# DDRSS0_CTL_CFG register map
Vendor: Texas Instruments
Registers are 32-bit, read-write, reset 0x0 unless marked. A register's access mark holds for its fields unless they carry their own. Offsets are as the file gives them; [hi:lo] are bit positions.

## DDRSS0_CTL_CFG (part 3 of 5)
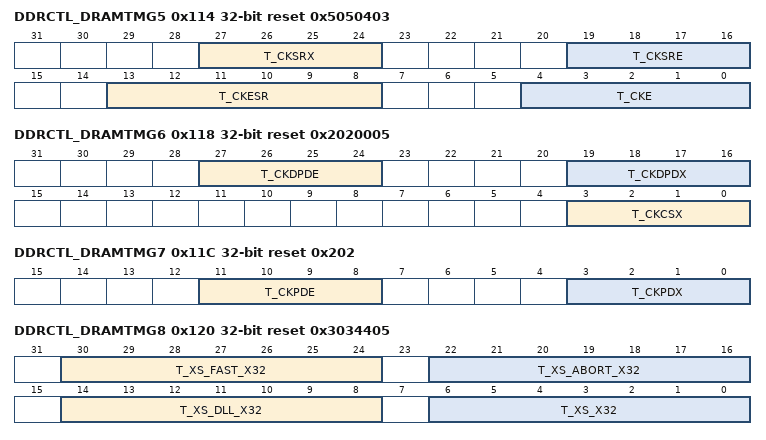
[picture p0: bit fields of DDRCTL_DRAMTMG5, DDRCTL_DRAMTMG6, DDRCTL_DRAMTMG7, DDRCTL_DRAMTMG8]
0x114 DDRCTL_DRAMTMG5 reset 0x5050403 — SDRAM Timing Register 5
  [27:24] T_CKSRX — This is the time before Self Refresh Exit that CK is maintained as a valid clock before issuing SRX.Specifies the clock stable time before SRX. Recommended settings: - mDDR: 1 - LPDDR2: 2 - LPDDR3: 2 - LPDDR4: tCKCKEH - DDR2: 1 - DDR3: tCKSRX - DDR4: tCKSRX When the controller is operating in 1:2 frequency ratio mode, program this to recommended value divided by two and round it up to next integer. Programming Mode: Quasi-dynamic Group 2 and Group 4
  [19:16] T_CKSRE — This is the time after Self Refresh Down Entry that CK is maintained as a valid clock.Specifies the clock disable delay after SRE. Recommended settings: - mDDR: 0 - LPDDR2: 2 - LPDDR3: 2 - LPDDR4: tCKELCK - DDR2: 1 - DDR3: max (10 ns, 5 tCK) - DDR4: max (10 ns, 5 tCK) (+ PL(parity latency)(*)) (*)Only if DDRCTL_CRCPARCTL1.caparity_disable_before_sr=0, this register should be increased by PL. When the controller is operating in 1:2 frequency ratio mode, program this to recommended value divided by two and round it up to next integer. Programming Mode: Quasi-dynamic Group 2 and Group 4
  [13:8] T_CKESR — Minimum CKE low width for Self refresh or Self refresh power down entry to exit timing in memory clock cycles.Recommended settings: - mDDR: tRFC - LPDDR2: tCKESR - LPDDR3: tCKESR - LPDDR4: max(tCKE, tSR) - DDR2: tCKE - DDR3: tCKE + 1 - DDR4: tCKE + 1 (+ PL(parity latency)(*)) (*)Only if DDRCTL_CRCPARCTL1.caparity_disable_before_sr=0, this register should be increased by PL. When the controller is operating in 1:2 frequency ratio mode, program this to recommended value divided by two and round it up to next integer. Programming Mode: Quasi-dynamic Group 2 and Group 4
  [4:0] T_CKE — Minimum number of cycles of CKE HIGH/LOW during power-down and self refresh.- LPDDR2/LPDDR3 mode: Set this to the larger of tCKE or tCKESR - LPDDR4 mode: Set this to the larger of tCKE or tSR. - Non-LPDDR2/non-LPDDR3/non-LPDDR4 designs: Set this to tCKE value. When the controller is operating in 1:2 frequency ratio mode, program this to (value described above)/2 and round it up to the next integer value. Unit: Clocks. Programming Mode: Quasi-dynamic Group 2 and Group 4
0x118 DDRCTL_DRAMTMG6 reset 0x2020005 — SDRAM Timing Register 6
  [27:24] T_CKDPDE — This is the time after Deep Power Down Entry that CK is maintained as a valid clock.Specifies the clock disable delay after DPDE. Recommended settings: - mDDR: 0 - LPDDR2: 2 - LPDDR3: 2 When the controller is operating in 1:2 frequency ratio mode, program this to recommended value divided by two and round it up to next integer. This is only present for designs supporting mDDR or LPDDR2/LPDDR3 devices. Programming Mode: Quasi-dynamic Group 2 and Group 4
  [19:16] T_CKDPDX — This is the time before Deep Power Down Exit that CK is maintained as a valid clock before issuing DPDX.Specifies the clock stable time before DPDX. Recommended settings: - mDDR: 1 - LPDDR2: 2 - LPDDR3: 2 When the controller is operating in 1:2 frequency ratio mode, program this to recommended value divided by two and round it up to next integer. This is only present for designs supporting mDDR or LPDDR2 devices. Programming Mode: Quasi-dynamic Group 2 and Group 4
  [3:0] T_CKCSX — This is the time before Clock Stop Exit that CK is maintained as a valid clock before issuing Clock Stop Exit.Specifies the clock stable time before next command after Clock Stop Exit. Recommended settings: - mDDR: 1 - LPDDR2: tXP + 2 - LPDDR3: tXP + 2 - LPDDR4: tXP + 2 When the controller is operating in 1:2 frequency ratio mode, program this to recommended value divided by two and round it up to next integer. This is only present for designs supporting mDDR or LPDDR2/LPDDR3/LPDDR4 devices. Programming Mode: Quasi-dynamic Group 2 and Group 4
0x11C DDRCTL_DRAMTMG7 reset 0x202 — SDRAM Timing Register 7
  [11:8] T_CKPDE — This is the time after Power Down Entry that CK is maintained as a valid clock.Specifies the clock disable delay after PDE. Recommended settings: - mDDR: 0 - LPDDR2: 2 - LPDDR3: 2 - LPDDR4: tCKELCK When using DDR2/3/4 SDRAM, this register should be set to the same value as DDRCTL_DRAMTMG5.t_cksre. When the controller is operating in 1:2 frequency ratio mode, program this to recommended value divided by two and round it up to next integer. This is only present for designs supporting mDDR or LPDDR2/LPDDR3/LPDDR4 devices. Programming Mode: Quasi-dynamic Group 2 and Group 4
  [3:0] T_CKPDX — This is the time before Power Down Exit that CK is maintained as a valid clock before issuing PDX.Specifies the clock stable time before PDX. Recommended settings: - mDDR: 0 - LPDDR2: 2 - LPDDR3: 2 - LPDDR4: 2 When using DDR2/3/4 SDRAM, this register should be set to the same value as DDRCTL_DRAMTMG5.t_cksrx. When the controller is operating in 1:2 frequency ratio mode, program this to recommended value divided by two and round it up to next integer. This is only present for designs supporting mDDR or LPDDR2/LPDDR3/LPDDR4 devices. Programming Mode: Quasi-dynamic Group 2 and Group 4
0x120 DDRCTL_DRAMTMG8 reset 0x3034405 — SDRAM Timing Register 8
  [30:24] T_XS_FAST_X32 — tXS_FAST: Exit Self Refresh to ZQCL, ZQCS and MRS (only CL, WR, RTP and Geardown mode).When the controller is operating in 1:2 frequency ratio mode, program this to the above value divided by 2 and round up to next integer value. Unit: Multiples of 32 clocks. Note: This is applicable to only ZQCL/ZQCS commands. Note: Ensure this is less than or equal to t_xs_x32. Programming Mode: Quasi-dynamic Group 2 and Group 4
  [22:16] T_XS_ABORT_X32 — tXS_ABORT: Exit Self Refresh to commands not requiring a locked DLL in Self Refresh Abort.When the controller is operating in 1:2 frequency ratio mode, program this to the above value divided by 2 and round up to next integer value. Unit: Multiples of 32 clocks. Note: Ensure this is less than or equal to t_xs_x32. Programming Mode: Quasi-dynamic Group 2 and Group 4
  [14:8] T_XS_DLL_X32 — tXSDLL: Exit Self Refresh to commands requiring a locked DLL.When the controller is operating in 1:2 frequency ratio mode, program this to the above value divided by 2 and round up to next integer value. Unit: Multiples of 32 clocks. Note: Used only for DDR2, DDR3 and DDR4 SDRAMs. Programming Mode: Quasi-dynamic Group 2 and Group 4
  [6:0] T_XS_X32 — tXS: Exit Self Refresh to commands not requiring a locked DLL.When the controller is operating in 1:2 frequency ratio mode, program this to the above value divided by 2 and round up to next integer value. Unit: Multiples of 32 clocks. Note: Used only for DDR2, DDR3 and DDR4 SDRAMs. Programming Mode: Quasi-dynamic Group 2 and Group 4
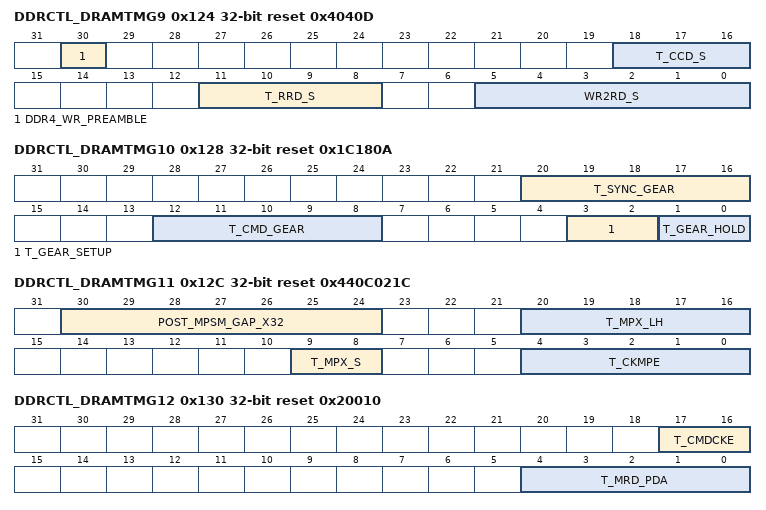
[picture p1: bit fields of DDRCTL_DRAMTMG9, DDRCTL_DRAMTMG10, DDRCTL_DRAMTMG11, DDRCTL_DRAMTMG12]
0x124 DDRCTL_DRAMTMG9 reset 0x4040D — SDRAM Timing Register 9
  [30] DDR4_WR_PREAMBLE — DDR4 Write preamble mode -0: 1tCK preamble - 1: 2tCK preamble Present only with MEMC_FREQ_RATIO=2 Programming Mode: Quasi-dynamic Group 2 and Group 4
  [18:16] T_CCD_S — tCCD_S: This is the minimum time between two reads or two writes for different bank group.For bank switching (from bank 'a' to bank 'b'), the minimum time is this value + 1. When the controller is operating in 1:2 frequency ratio mode, program this to (tCCD_S/2) and round it up to the next integer value. Present only in designs configured to support DDR4. Unit: clocks. Programming Mode: Quasi-dynamic Group 2 and Group 4
  [11:8] T_RRD_S — tRRD_S: Minimum time between activates from bank 'a' to bank 'b' for different bank group.When the controller is operating in 1:2 frequency ratio mode, program this to (tRRD_S/2) and round it up to the next integer value. Present only in designs configured to support DDR4. Unit: Clocks. Programming Mode: Quasi-dynamic Group 2 and Group 4
  [5:0] WR2RD_S — CWL + PL + BL/2 + tWTR_S Minimum time from write command to read command for different bank group.Includes time for bus turnaround, recovery times, and all per-bank, per-rank, and global constraints. Present only in designs configured to support DDR4. Unit: Clocks. Where: - CWL = CAS write latency - PL = Parity latency - BL = burst length. This must match the value programmed in the BL bit of the mode register to the SDRAM - tWTR_S = internal write to read command delay for different bank group. This comes directly from the SDRAM specification. When the controller is operating in 1:2 mode, divide the value calculated using the above equation by 2, and round it up to next integer. Programming Mode: Quasi-dynamic Group 1 and Group 2 and Group 4
0x128 DDRCTL_DRAMTMG10 reset 0x1C180A — SDRAM Timing Register 10
  [20:16] T_SYNC_GEAR — Indicates the time between MRS command and the sync pulse time.This must be even number of clocks. For DDR4-2666 and DDR4-3200, this parameter is defined as tMOD(min)+4nCK tMOD(min) is greater of 24nCK or 15ns 15ns / .625ns = 24 Max value for this register is 24+4 = 28 When the controller is operating in 1:2 mode, program this to (tSYNC_GEAR/2) and round it up to the next integer value. Unit: Clocks Programming Mode: Quasi-dynamic Group 2 and Group 4
  [12:8] T_CMD_GEAR — Sync pulse to first valid command.For DDR4-2666 and DDR4-3200, this parameter is defined as tMOD(min) tMOD(min) is greater of 24nCK or 15ns 15ns / .625ns = 24 Max value for this register is 24 When the controller is operating in 1:2 mode, program this to (tCMD_GEAR/2) and round it up to the next integer value. Unit: Clocks Programming Mode: Quasi-dynamic Group 2 and Group 4
  [3:2] T_GEAR_SETUP — Geardown setup time.Minimum value of this register is 1. Zero is invalid. For DDR4-2666 and DDR4-3200, this parameter is defined as 2 clks When the controller is operating in 1:2 frequency ratio mode, program this to (tGEAR_setup/2) and round it up to the next integer value. Unit: Clocks Programming Mode: Quasi-dynamic Group 2 and Group 4
  [1:0] T_GEAR_HOLD — Geardown hold time.Minimum value of this register is 1. Zero is invalid. For DDR4-2666 and DDR4-3200, this parameter is defined as 2 clks When the controller is operating in 1:2 frequency ratio mode, program this to (tGEAR_hold/2) and round it up to the next integer value. Unit: Clocks Programming Mode: Quasi-dynamic Group 2 and Group 4
0x12C DDRCTL_DRAMTMG11 reset 0x440C021C — SDRAM Timing Register 11
  [30:24] POST_MPSM_GAP_X32 — tXMPDLL: This is the minimum Exit MPSM to commands requiring a locked DLL.When the controller is operating in 1:2 frequency ratio mode, program this to (tXMPDLL/2) and round it up to the next integer value. Present only in designs configured to support DDR4. Unit: Multiples of 32 clocks. Programming Mode: Quasi-dynamic Group 2 and Group 4
  [20:16] T_MPX_LH — tMPX_LH: This is the minimum CS_n Low hold time to CKE rising edge.When the controller is operating in 1:2 frequency ratio mode, program this to RoundUp(tMPX_LH/2)+1. Present only in designs configured to support DDR4. Unit: clocks. Programming Mode: Quasi-dynamic Group 2 and Group 4
  [9:8] T_MPX_S — tMPX_S: Minimum time CS setup time to CKE.When the controller is operating in 1:2 frequency ratio mode, program this to (tMPX_S/2) and round it up to the next integer value. Present only in designs configured to support DDR4. Unit: Clocks. Programming Mode: Quasi-dynamic Group 2 and Group 4
  [4:0] T_CKMPE — tCKMPE: Minimum valid clock requirement after MPSM entry.Present only in designs configured to support DDR4. Unit: Clocks. When the controller is operating in 1:2 frequency ratio mode, divide the value calculated using the above equation by 2, and round it up to next integer. Programming Mode: Quasi-dynamic Group 2 and Group 4
0x130 DDRCTL_DRAMTMG12 reset 0x20010 — SDRAM Timing Register 12
  [17:16] T_CMDCKE — tCMDCKE: Delay from valid command to CKE input LOW.Set this to the larger of tESCKE or tCMDCKE When the controller is operating in 1:2 frequency ratio mode, program this to (max(tESCKE, tCMDCKE)/2) and round it up to the next integer value. Programming Mode: Quasi-dynamic Group 2 and Group 4
  [4:0] T_MRD_PDA — tMRD_PDA: This is the Mode Register Set command cycle time in PDA mode.When the controller is operating in 1:2 frequency ratio mode, program this to (tMRD_PDA/2) and round it up to the next integer value. Programming Mode: Quasi-dynamic Group 2 and Group 4
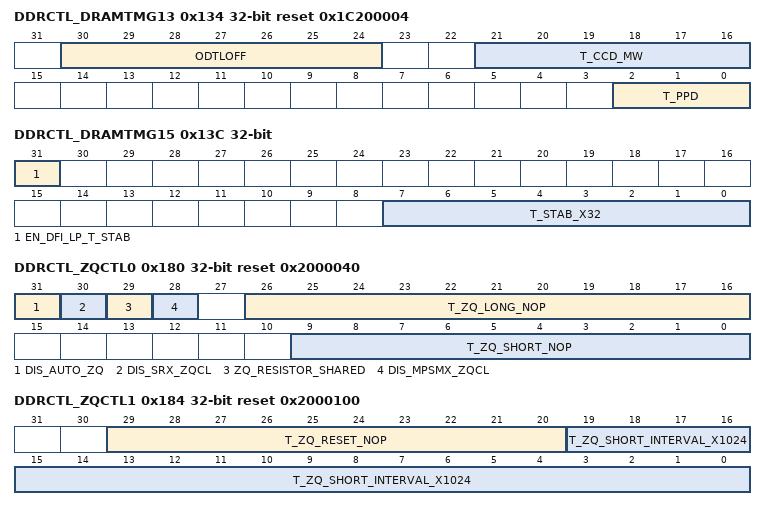
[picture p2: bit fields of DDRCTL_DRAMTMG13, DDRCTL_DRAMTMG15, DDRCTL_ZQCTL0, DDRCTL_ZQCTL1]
0x134 DDRCTL_DRAMTMG13 reset 0x1C200004 — SDRAM Timing Register 13
  [30:24] ODTLOFF — LPDDR4: tODTLoff: This is the latency from CAS-2 command to tODToff reference. When the controller is operating in 1:2 frequency ratio mode, program this to (tODTLoff/2) and round it up to the next integer value. Unit: Clocks. Programming Mode: Quasi-dynamic Group 2 and Group 4
  [21:16] T_CCD_MW — LPDDR4: tCCDMW: This is the minimum time from write or masked write to masked write command for same bank. When the controller is operating in 1:2 frequency ratio mode, program this to (tCCDMW/2) and round it up to the next integer value. Unit: Clocks. Programming Mode: Quasi-dynamic Group 2 and Group 4
  [2:0] T_PPD — LPDDR4: tPPD: This is the minimum time from precharge to precharge command. When the controller is operating in 1:2 frequency ratio mode, program this to (tPPD/2) and round it up to the next integer value. Unit: Clocks. Programming Mode: Quasi-dynamic Group 2 and Group 4
0x138 DDRCTL_DRAMTMG14 reset 0xA0 — SDRAM Timing Register 14
  [11:0] T_XSR — tXSR: Exit Self Refresh to any command.When the controller is operating in 1:2 frequency ratio mode, program this to the above value divided by 2 and round up to next integer value. Note: Used only for mDDR/LPDDR2/LPDDR3/LPDDR4 mode. Programming Mode: Quasi-dynamic Group 2 and Group 4
0x13C DDRCTL_DRAMTMG15 — SDRAM Timing Register 15
  [31] EN_DFI_LP_T_STAB — -1 - Enable using tSTAB when exiting DFI LP. Needs to be set when the PHY is stopping the clock during DFI LP to save maximum power. - 0 - Disable using tSTAB when exiting DFI LP Programming Mode: Quasi-dynamic Group 2 and Group 4
  [7:0] T_STAB_X32 — tSTAB: Stabilization time.It is required in the following two cases for DDR3/DDR4 RDIMM : - when exiting power saving mode, if the clock was stopped, after re-enabling it the clock must be stable for a time specified by tSTAB - in the case of input clock frequency change (DDR4) - after issuing control words that refers to clock timing (Specification: 6us for DDR3, 5us for DDR4) When the controller is operating in 1:2 frequency ratio mode, program this to recommended value divided by two and round it up to next integer. Unit: Multiples of 32 clock cycles. Programming Mode: Quasi-dynamic Group 2 and Group 4
0x180 DDRCTL_ZQCTL0 reset 0x2000040 — ZQ Control Register 0
  [31] DIS_AUTO_ZQ — -1 - Disable uMCTL2 generation of ZQCS/MPC(ZQ calibration) command. Register DDRCTL_DBGCMD.zq_calib_short can be used instead to issue ZQ calibration request from APB module. - 0 - Internally generate ZQCS/MPC(ZQ calibration) commands based on DDRCTL_ZQCTL1.t_zq_short_interval_x1024. This is only present for designs supporting DDR3/DDR4 or LPDDR2/LPDDR3/LPDDR4 devices. Programming Mode: Dynamic
  [30] DIS_SRX_ZQCL — -1 - Disable issuing of ZQCL/MPC(ZQ calibration) command at Self-Refresh/SR-Powerdown exit. Only applicable when run in DDR3 or DDR4 or LPDDR2 or LPDDR3 or LPDDR4 mode. - 0 - Enable issuing of ZQCL/MPC(ZQ calibration) command at Self-Refresh/SR-Powerdown exit. Only applicable when run in DDR3 or DDR4 or LPDDR2 or LPDDR3 or LPDDR4 mode. This is only present for designs supporting DDR3/DDR4 or LPDDR2/LPDDR3/LPDDR4 devices. Programming Mode: Quasi-dynamic Group 2 and Group 4
  [29] ZQ_RESISTOR_SHARED — -1 - Denotes that ZQ resistor is shared between ranks. Means ZQinit/ZQCL/ZQCS/MPC(ZQ calibration) commands are sent to one rank at a time with tZQinit/tZQCL/tZQCS/tZQCAL/tZQLAT timing met between commands so that commands to different ranks do not overlap. - 0 - ZQ resistor is not shared. This is only present for designs supporting DDR3/DDR4 or LPDDR2/LPDDR3/LPDDR4 devices. Programming Mode: Static
  [28] DIS_MPSMX_ZQCL — -1 - Disable issuing of ZQCL command at Maximum Power Saving Mode exit. Only applicable when run in DDR4 mode. - 0 - Enable issuing of ZQCL command at Maximum Power Saving Mode exit. Only applicable when run in DDR4 mode. This is only present for designs supporting DDR4 devices. Note: Do not issue ZQCL command at Maximum Power Save Mode exit if the UMCTL2_SHARED_AC configuration parameter is set. Program it to 1'b1. The software can send ZQCS after exiting MPSM mode. Programming Mode: Static
  [26:16] T_ZQ_LONG_NOP — tZQoper for DDR3/DDR4, tZQCL for LPDDR2/LPDDR3, tZQCAL for LPDDR4: Number of DFI clock cycles of NOP required after a ZQCL (ZQ calibration long)/MPC(ZQ Start) command is issued to SDRAM. When the controller is operating in 1:2 frequency ratio mode: DDR3/DDR4: program this to tZQoper/2 and round it up to the next integer value. LPDDR2/LPDDR3: program this to tZQCL/2 and round it up to the next integer value. LPDDR4: program this to tZQCAL/2 and round it up to the next integer value. This is only present for designs supporting DDR3/DDR4 or LPDDR2/LPDDR3/LPDDR4 devices. Programming Mode: Static
  [9:0] T_ZQ_SHORT_NOP — tZQCS for DDR3/DD4/LPDDR2/LPDDR3, tZQLAT for LPDDR4: Number of DFI clock cycles of NOP required after a ZQCS (ZQ calibration short)/MPC(ZQ Latch) command is issued to SDRAM. When the controller is operating in 1:2 frequency ratio mode, program this to tZQCS/2 and round it up to the next integer value. This is only present for designs supporting DDR3/DDR4 or LPDDR2/LPDDR3/LPDDR4 devices. Programming Mode: Static
0x184 DDRCTL_ZQCTL1 reset 0x2000100 — ZQ Control Register 1
  [29:20] T_ZQ_RESET_NOP — tZQReset: Number of DFI clock cycles of NOP required after a ZQReset (ZQ calibration Reset) command is issued to SDRAM.When the controller is operating in 1:2 frequency ratio mode, program this to tZQReset/2 and round it up to the next integer value. This is only present for designs supporting LPDDR2/LPDDR3/LPDDR4 devices. Programming Mode: Static
  [19:0] T_ZQ_SHORT_INTERVAL_X1024 — Average interval to wait between automatically issuing ZQCS (ZQ calibration short)/MPC(ZQ calibration) commands to DDR3/DDR4/LPDDR2/LPDDR3/LPDDR4 devices.Meaningless, if DDRCTL_ZQCTL0.dis_auto_zq=1. Unit: 1024 DFI clock cycles. This is only present for designs supporting DDR3/DDR4 or LPDDR2/LPDDR3/LPDDR4 devices. Programming Mode: Static
0x188 DDRCTL_ZQCTL2 access not given — ZQ Control Register 2
  [0] ZQ_RESET — Setting this register bit to 1 triggers a ZQ Reset operation.When the ZQ Reset operation is complete, the uMCTL2 automatically clears this bit. It is recommended NOT to set this signal if in Init, Self-Refresh(except LPDDR4) or SR-Powerdown(LPDDR4) or Deep power-down operating modes. This is only present for designs supporting LPDDR2/LPDDR3/LPDDR4 devices. Programming Mode: Dynamic (access W1S)
0x18C DDRCTL_ZQSTAT ro — ZQ Status Register
  [0] ZQ_RESET_BUSY — SoC core may initiate a ZQ Reset operation only if this signal is low.This signal goes high in the clock after the uMCTL2 accepts the ZQ Reset request. It goes low when the ZQ Reset command is issued to the SDRAM and the associated NOP period is over. It is recommended not to perform ZQ Reset commands when this signal is high. - 0 - Indicates that the SoC core can initiate a ZQ Reset operation - 1 - Indicates that ZQ Reset operation is in progress Programming Mode: Dynamic
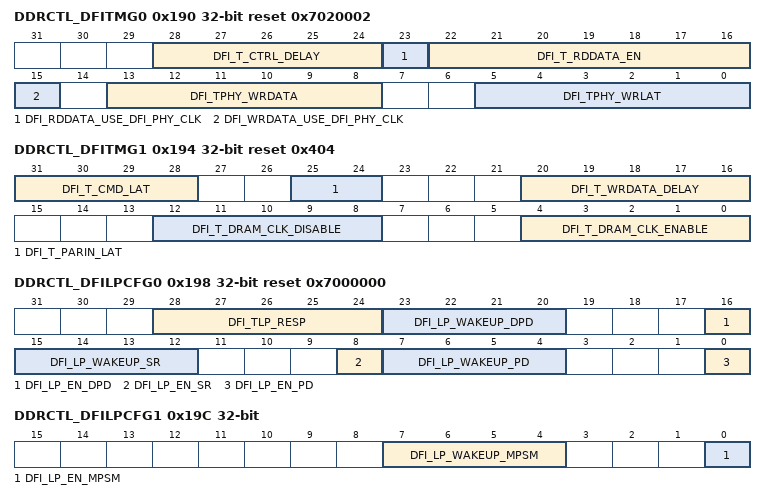
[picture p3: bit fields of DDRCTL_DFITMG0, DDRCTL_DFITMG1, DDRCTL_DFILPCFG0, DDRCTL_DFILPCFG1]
0x190 DDRCTL_DFITMG0 reset 0x7020002 — DFI Timing Register 0
  [28:24] DFI_T_CTRL_DELAY — Specifies the number of DFI clock cycles after an assertion or de-assertion of the DFI control signals that the control signals at the PHY-DRAM interface reflect the assertion or de-assertion.If the DFI clock and the memory clock are not phase-aligned, this timing parameter should be rounded up to the next integer value. Note that if using RDIMM/LRDIMM, it is necessary to increment this parameter by RDIMM's/LRDIMM's extra cycle of latency in terms of DFI clock. Programming Mode: Quasi-dynamic Group 4
  [23] DFI_RDDATA_USE_DFI_PHY_CLK — Defines whether dfi_rddata_en/dfi_rddata/dfi_rddata_valid is generated using HDR (DFI clock) or SDR (DFI PHY clock) values.Selects whether value in DDRCTL_DFITMG0.dfi_t_rddata_en is in terms of HDR (DFI clock) or SDR (DFI PHY clock) cycles: - 0 in terms of HDR (DFI clock) cycles - 1 in terms of SDR (DFI PHY clock) cycles Refer to PHY specification for correct value. If using a DWC DDR3/2 PHY, DWC DDR2/3-Lite/mDDR PHY, DWC DDR multiPHY or DWC Gen2 DDR multiPHY, this field must be set to 0 otherwise: - If MEMC_PROG_FREQ_RATIO=1 and DDRCTL_MSTR.frequency_ratio=1, this field should be set to 0 - Else, it must be set to 1 Programming Mode: Static
  [22:16] DFI_T_RDDATA_EN — Time from the assertion of a read command on the DFI interface to the assertion of the dfi_rddata_en signal.Refer to PHY specification for correct value. This corresponds to the DFI parameter trddata_en. Note that, depending on the PHY, if using RDIMM/LRDIMM, it may be necessary to use the adjusted value of CL in the calculation of trddata_en. This is to compensate for the extra cycle(s) of latency through the RDIMM/LRDIMM. Unit: DFI clock cycles or DFI PHY clock cycles, depending on DDRCTL_DFITMG0.dfi_rddata_use_dfi_phy_clk. Programming Mode: Quasi-dynamic Group 1 and Group 4
  [15] DFI_WRDATA_USE_DFI_PHY_CLK — Defines whether dfi_wrdata_en/dfi_wrdata/dfi_wrdata_mask is generated using HDR (DFI clock) or SDR (DFI PHY clock) values Selects whether value inDDRCTL_DFITMG0.dfi_tphy_wrlat is in terms of HDR (DFI clock) or SDR (DFI PHY clock) cycles Selects whether value in DDRCTL_DFITMG0.dfi_tphy_wrdata is in terms of HDR (DFI clock) or SDR (DFI PHY clock) cycles - 0 in terms of HDR (DFI clock) cycles - 1 in terms of SDR (DFI PHY clock) cycles Refer to PHY specification for correct value. If using a DWC DDR3/2 PHY, DWC DDR2/3-Lite/mDDR PHY, DWC DDR multiPHY or DWC Gen2 DDR multiPHY, this field must be set to 0 otherwise: - If MEMC_PROG_FREQ_RATIO=1 and DDRCTL_MSTR.frequency_ratio=1, this field should be set to 0 - Else, it must be set to 1 Programming Mode: Static
  [13:8] DFI_TPHY_WRDATA — Specifies the number of clock cycles between when dfi_wrdata_en is asserted to when the associated write data is driven on the dfi_wrdata signal.This corresponds to the DFI timing parameter tphy_wrdata. Refer to PHY specification for correct value. Note, max supported value is 8. Unit: DFI clock cycles or DFI PHY clock cycles, depending on DDRCTL_DFITMG0.dfi_wrdata_use_dfi_phy_clk. Programming Mode: Quasi-dynamic Group 4
  [5:0] DFI_TPHY_WRLAT — Write latency Number of clocks from the write command to write data enable (dfi_wrdata_en).This corresponds to the DFI timing parameter tphy_wrlat. Refer to PHY specification for correct value.Note that, depending on the PHY, if using RDIMM/LRDIMM, it may be necessary to use the adjusted value of CL in the calculation of tphy_wrlat. This is to compensate for the extra cycle(s) of latency through the RDIMM/LRDIMM. For LPDDR4, dfi_tphy_wrlat&gt;60 is not supported. Unit: DFI clock cycles or DFI PHY clock cycles, depending on DDRCTL_DFITMG0.dfi_wrdata_use_dfi_phy_clk. Programming Mode: Quasi-dynamic Group 1 and Group 4
0x194 DDRCTL_DFITMG1 reset 0x404 — DFI Timing Register 1
  [31:28] DFI_T_CMD_LAT — Specifies the number of DFI PHY clock cycles between when the dfi_cs signal is asserted and when the associated command is driven.This field is used for CAL mode, should be set to '0' or the value which matches the CAL mode register setting in the DRAM. If the PHY can add the latency for CAL mode, this should be set to '0'. Valid Range: 0, 3, 4, 5, 6, and 8 Programming Mode: Quasi-dynamic Group 2 and Group 4
  [25:24] DFI_T_PARIN_LAT — Specifies the number of DFI PHY clock cycles between when the dfi_cs signal is asserted and when the associated dfi_parity_in signal is driven.Programming Mode: Quasi-dynamic Group 4
  [20:16] DFI_T_WRDATA_DELAY — Specifies the number of DFI clock cycles between when the dfi_wrdata_en signal is asserted and when the corresponding write data transfer is completed on the DRAM bus.This corresponds to the DFI timing parameter twrdata_delay. Refer to PHY specification for correct value. For DFI 3.0 PHY, set to twrdata_delay, a new timing parameter introduced in DFI 3.0. For DFI 2.1 PHY, set to tphy_wrdata + (delay of DFI write data to the DRAM). Value to be programmed is in terms of DFI clocks, not PHY clocks. In FREQ_RATIO=2, divide PHY's value by 2 and round up to next integer. If using DDRCTL_DFITMG0.dfi_wrdata_use_dfi_phy_clk=1, add 1 to the value. Unit: Clocks Programming Mode: Quasi-dynamic Group 4
  [12:8] DFI_T_DRAM_CLK_DISABLE — Specifies the number of DFI clock cycles from the assertion of the dfi_dram_clk_disable signal on the DFI until the clock to the DRAM memory devices, at the PHY-DRAM boundary, maintains a low value.If the DFI clock and the memory clock are not phase aligned, this timing parameter should be rounded up to the next integer value. Programming Mode: Quasi-dynamic Group 4
  [4:0] DFI_T_DRAM_CLK_ENABLE — Specifies the number of DFI clock cycles from the de-assertion of the dfi_dram_clk_disable signal on the DFI until the first valid rising edge of the clock to the DRAM memory devices, at the PHY-DRAM boundary.If the DFI clock and the memory clock are not phase aligned, this timing parameter should be rounded up to the next integer value. Programming Mode: Quasi-dynamic Group 4
0x198 DDRCTL_DFILPCFG0 reset 0x7000000 — DFI Low Power Configuration Register 0
  [28:24] DFI_TLP_RESP — Setting in DFI clock cycles for DFI's tlp_resp time.Same value is used for both Power Down, Self Refresh, Deep Power Down and Maximum Power Saving modes. DFI 2.1 specification onwards, recommends using a fixed value of 7 always. Programming Mode: Static
  [23:20] DFI_LP_WAKEUP_DPD — Value in DFI clock cycles to drive on dfi_lp_wakeup signal when Deep Power Down mode is entered.Determines the DFI's tlp_wakeup time: - 0x0 - 16 cycles - 0x1 - 32 cycles - 0x2 - 64 cycles - 0x3 - 128 cycles - 0x4 - 256 cycles - 0x5 - 512 cycles - 0x6 - 1024 cycles - 0x7 - 2048 cycles - 0x8 - 4096 cycles - 0x9 - 8192 cycles - 0xA - 16384 cycles - 0xB - 32768 cycles - 0xC - 65536 cycles - 0xD - 131072 cycles - 0xE - 262144 cycles - 0xF - Unlimited This is only present for designs supporting mDDR or LPDDR2/LPDDR3 devices. Programming Mode: Static
  [16] DFI_LP_EN_DPD — Enables DFI Low Power interface handshaking during Deep Power Down Entry/Exit.- 0 - Disabled - 1 - Enabled This is only present for designs supporting mDDR or LPDDR2/LPDDR3 devices. Programming Mode: Static
  [15:12] DFI_LP_WAKEUP_SR — Value in DFI clpck cycles to drive on dfi_lp_wakeup signal when Self Refresh mode is entered.Determines the DFI's tlp_wakeup time: - 0x0 - 16 cycles - 0x1 - 32 cycles - 0x2 - 64 cycles - 0x3 - 128 cycles - 0x4 - 256 cycles - 0x5 - 512 cycles - 0x6 - 1024 cycles - 0x7 - 2048 cycles - 0x8 - 4096 cycles - 0x9 - 8192 cycles - 0xA - 16384 cycles - 0xB - 32768 cycles - 0xC - 65536 cycles - 0xD - 131072 cycles - 0xE - 262144 cycles - 0xF - Unlimited Programming Mode: Static
  [8] DFI_LP_EN_SR — Enables DFI Low Power interface handshaking during Self Refresh Entry/Exit.- 0 - Disabled - 1 - Enabled Programming Mode: Static
  [7:4] DFI_LP_WAKEUP_PD — Value in DFI clock cycles to drive on dfi_lp_wakeup signal when Power Down mode is entered.Determines the DFI's tlp_wakeup time: - 0x0 - 16 cycles - 0x1 - 32 cycles - 0x2 - 64 cycles - 0x3 - 128 cycles - 0x4 - 256 cycles - 0x5 - 512 cycles - 0x6 - 1024 cycles - 0x7 - 2048 cycles - 0x8 - 4096 cycles - 0x9 - 8192 cycles - 0xA - 16384 cycles - 0xB - 32768 cycles - 0xC - 65536 cycles - 0xD - 131072 cycles - 0xE - 262144 cycles - 0xF - Unlimited Programming Mode: Static
  [0] DFI_LP_EN_PD — Enables DFI Low Power interface handshaking during Power Down Entry/Exit.- 0 - Disabled - 1 - Enabled Programming Mode: Static
0x19C DDRCTL_DFILPCFG1 — DFI Low Power Configuration Register 1
  [7:4] DFI_LP_WAKEUP_MPSM — Value in DFI clock cycles to drive on dfi_lp_wakeup signal when Maximum Power Saving Mode is entered.Determines the DFI's tlp_wakeup time: - 0x0 - 16 cycles - 0x1 - 32 cycles - 0x2 - 64 cycles - 0x3 - 128 cycles - 0x4 - 256 cycles - 0x5 - 512 cycles - 0x6 - 1024 cycles - 0x7 - 2048 cycles - 0x8 - 4096 cycles - 0x9 - 8192 cycles - 0xA - 16384 cycles - 0xB - 32768 cycles - 0xC - 65536 cycles - 0xD - 131072 cycles - 0xE - 262144 cycles - 0xF - Unlimited This is only present for designs supporting DDR4 devices. Programming Mode: Static
  [0] DFI_LP_EN_MPSM — Enables DFI Low Power interface handshaking during Maximum Power Saving Mode Entry/Exit.- 0 - Disabled - 1 - Enabled This is only present for designs supporting DDR4 devices. Programming Mode: Static
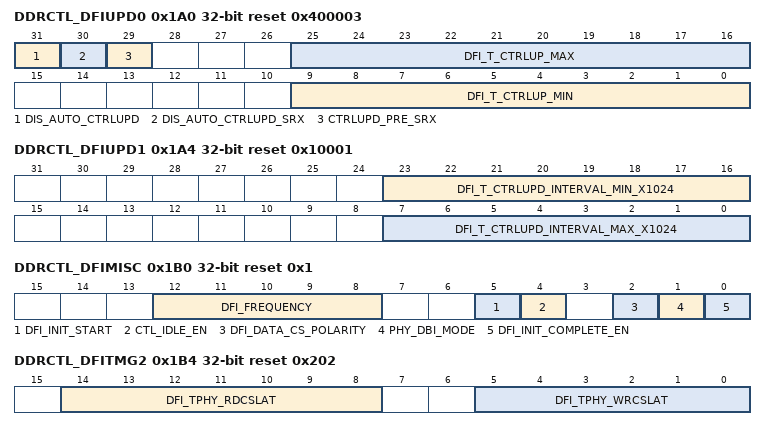
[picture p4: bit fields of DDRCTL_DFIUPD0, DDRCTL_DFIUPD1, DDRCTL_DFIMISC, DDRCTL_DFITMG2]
0x1A0 DDRCTL_DFIUPD0 reset 0x400003 — DFI Update Register 0
  [31] DIS_AUTO_CTRLUPD — When '1', disable the automatic dfi_ctrlupd_req generation by the uMCTL2.The core must issue the dfi_ctrlupd_req signal using register DDRCTL_DBGCMD.ctrlupd. When '0', uMCTL2 issues dfi_ctrlupd_req periodically. Programming Mode: Quasi-dynamic Group 3
  [30] DIS_AUTO_CTRLUPD_SRX — When '1', disable the automatic dfi_ctrlupd_req generation by the uMCTL2 at self-refresh exit.When '0', uMCTL2 issues a dfi_ctrlupd_req before or after exiting self-refresh, depending on DDRCTL_DFIUPD0.ctrlupd_pre_srx. Programming Mode: Static
  [29] CTRLUPD_PRE_SRX — Selects dfi_ctrlupd_req requirements at SRX: -0 : send ctrlupd after SRX - 1 : send ctrlupd before SRX If DDRCTL_DFIUPD0.dis_auto_ctrlupd_srx=1, this register has no impact, because no dfi_ctrlupd_req will be issued when SRX. Programming Mode: Static
  [25:16] DFI_T_CTRLUP_MAX — Specifies the maximum number of DFI clock cycles that the dfi_ctrlupd_req signal can assert.Lowest value to assign to this variable is 0x40. Programming Mode: Static
  [9:0] DFI_T_CTRLUP_MIN — Specifies the minimum number of DFI clock cycles that the dfi_ctrlupd_req signal must be asserted.The uMCTL2 expects the PHY to respond within this time. If the PHY does not respond, the uMCTL2 will de-assert dfi_ctrlupd_req after dfi_t_ctrlup_min + 2 cycles. Lowest value to assign to this variable is 0x3. Programming Mode: Static
0x1A4 DDRCTL_DFIUPD1 reset 0x10001 — DFI Update Register 1
  [23:16] DFI_T_CTRLUPD_INTERVAL_MIN_X1024 — This is the minimum amount of time between uMCTL2 initiated DFI update requests (which is executed whenever the uMCTL2 is idle).Set this number higher to reduce the frequency of update requests, which can have a small impact on the latency of the first read request when the uMCTL2 is idle. Minimum allowed value for this field is 1. Unit: 1024 DFI clock cycles Programming Mode: Static
  [7:0] DFI_T_CTRLUPD_INTERVAL_MAX_X1024 — This is the maximum amount of time between uMCTL2 initiated DFI update requests.This timer resets with each update request when the timer expires dfi_ctrlupd_req is sent and traffic is blocked until the dfi_ctrlupd_ackx is received. PHY can use this idle time to recalibrate the delay lines to the DLLs. The DFI controller update is also used to reset PHY FIFO pointers in case of data capture errors. Updates are required to maintain calibration over PVT, but frequent updates may impact performance. Minimum allowed value for this field is 1. Note: Value programmed for DDRCTL_DFIUPD1.dfi_t_ctrlupd_interval_max_x1024 must be greater than DDRCTL_DFIUPD1.dfi_t_ctrlupd_interval_min_x1024. Unit: 1024 DFI clock cycles Programming Mode: Static
0x1A8 DDRCTL_DFIUPD2 reset 0x80000000 — DFI Update Register 2
  [31] DFI_PHYUPD_EN — Enables the support for acknowledging PHY-initiated updates: -0 - Disabled - 1 - Enabled Programming Mode: Static
0x1B0 DDRCTL_DFIMISC reset 0x1 — DFI Miscellaneous Control Register
  [12:8] DFI_FREQUENCY — Indicates the operating frequency of the system.The number of supported frequencies and the mapping of signal values to clock frequencies are defined by the PHY. Programming Mode: Quasi-dynamic Group 1
  [5] DFI_INIT_START — PHY init start request signal.When asserted it triggers the PHY init start request Programming Mode: Quasi-dynamic Group 3
  [4] CTL_IDLE_EN — Enables support of ctl_idle signal, which is non-DFI related pin.See signal description of ctl_idle signal for further details of ctl_idle functionality. Programming Mode: Static
  [2] DFI_DATA_CS_POLARITY — Defines polarity of dfi_wrdata_cs and dfi_rddata_cs signals.- 0: Signals are active low - 1: Signals are active high Programming Mode: Static
  [1] PHY_DBI_MODE — DBI implemented in DDRC or PHY.- 0 - DDRC implements DBI functionality. - 1 - PHY implements DBI functionality. Present only in designs configured to support DDR4 and LPDDR4. Programming Mode: Static
  [0] DFI_INIT_COMPLETE_EN — PHY initialization complete enable signal.When asserted the dfi_init_complete signal can be used to trigger SDRAM initialisation Programming Mode: Quasi-dynamic Group 3
0x1B4 DDRCTL_DFITMG2 reset 0x202 — DFI Timing Register 2
  [14:8] DFI_TPHY_RDCSLAT — Number of DFI PHY clock cycles between when a read command is sent on the DFI control interface and when the associated dfi_rddata_cs signal is asserted.This corresponds to the DFI timing parameter tphy_rdcslat. Refer to PHY specification for correct value. Programming Mode: Quasi-dynamic Group 2 and Group 4
  [5:0] DFI_TPHY_WRCSLAT — Number of DFI PHY clock cycles between when a write command is sent on the DFI control interface and when the associated dfi_wrdata_cs signal is asserted.This corresponds to the DFI timing parameter tphy_wrcslat. Refer to PHY specification for correct value. Programming Mode: Quasi-dynamic Group 2 and Group 4
0x1B8 DDRCTL_DFITMG3 — DFI Timing Register 3
  [4:0] DFI_T_GEARDOWN_DELAY — The delay from dfi_geardown_en assertion to the time of the PHY being ready to receive commands.Refer to PHY specification for correct value. When the controller is operating in 1:2 frequency ratio mode, program this to (tgeardown_delay/2) and round it up to the next integer value. Unit: Clocks Programming Mode: Static
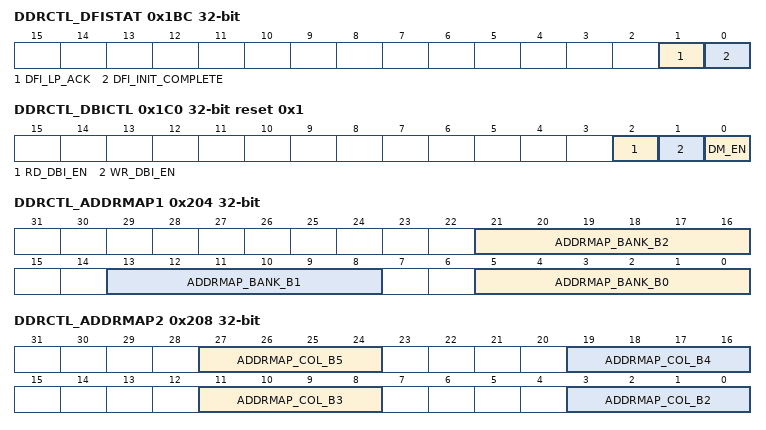
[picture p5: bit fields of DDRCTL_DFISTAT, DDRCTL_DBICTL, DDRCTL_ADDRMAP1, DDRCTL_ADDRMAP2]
0x1BC DDRCTL_DFISTAT ro — DFI Status Register
  [1] DFI_LP_ACK — Stores the value of the dfi_lp_ack input to the controller.Programming Mode: Dynamic
  [0] DFI_INIT_COMPLETE — The status flag register which announces when the DFI initialization has been completed.The DFI INIT triggered by dfi_init_start signal and then the dfi_init_complete flag is polled to know when the initialization is done. Programming Mode: Dynamic
0x1C0 DDRCTL_DBICTL reset 0x1 — DM/DBI Control Register
  [2] RD_DBI_EN — Read DBI enable signal in DDRC.- 0 - Read DBI is disabled. - 1 - Read DBI is enabled. This signal must be set the same value as DRAM's mode register. - DDR4: MR5 bit A12. When x4 devices are used, this signal must be set to 0. - LPDDR4: MR3[6] Programming Mode: Quasi-dynamic Group 1
  [1] WR_DBI_EN — Write DBI enable signal in DDRC.- 0 - Write DBI is disabled. - 1 - Write DBI is enabled. This signal must be set the same value as DRAM's mode register. - DDR4: MR5 bit A11. When x4 devices are used, this signal must be set to 0. - LPDDR4: MR3[7] Programming Mode: Quasi-dynamic Group 1
  [0] DM_EN — DM enable signal in DDRC.- 0 - DM is disabled. - 1 - DM is enabled. This signal must be set the same logical value as DRAM's mode register. - DDR4: Set this to same value as MR5 bit A10. When x4 devices are used, this signal must be set to 0. - LPDDR4: Set this to inverted value of MR13[5] which is opposite polarity from this signal Programming Mode: Quasi-dynamic Group 3
0x1C4 DDRCTL_DFIPHYMSTR reset 0x1 — DFI PHY Master
  [0] DFI_PHYMSTR_EN — Enables the PHY Master Interface: -0 - Disabled - 1 - Enabled Programming Mode: Dynamic
0x200 DDRCTL_ADDRMAP0 — Address Map Register 0
  [4:0] ADDRMAP_CS_BIT0 — Selects the HIF address bit used as rank address bit 0.Valid Range: 0 to 29, and 31 Internal Base: 6 The selected HIF address bit is determined by adding the internal base to the value of this field. If unused, set to 31 and then rank address bit 0 is set to 0. Programming Mode: Static
0x204 DDRCTL_ADDRMAP1 — Address Map Register 1
  [21:16] ADDRMAP_BANK_B2 — Selects the HIF address bit used as bank address bit 2.Valid Range: 0 to 31 and 63 Internal Base: 4 The selected HIF address bit is determined by adding the internal base to the value of this field. If unused, set to 63 and then bank address bit 2 is set to 0. Programming Mode: Static
  [13:8] ADDRMAP_BANK_B1 — Selects the HIF address bits used as bank address bit 1.Valid Range: 0 to 32 and 63 Internal Base: 3 The selected HIF address bit for each of the bank address bits is determined by adding the internal base to the value of this field. If unused, set to 63 and then bank address bit 1 is set to 0. Programming Mode: Static
  [5:0] ADDRMAP_BANK_B0 — Selects the HIF address bits used as bank address bit 0.Valid Range: 0 to 32 and 63 Internal Base: 2 The selected HIF address bit for each of the bank address bits is determined by adding the internal base to the value of this field. If unused, set to 63 and then bank address bit 0 is set to 0. Programming Mode: Static
0x208 DDRCTL_ADDRMAP2 — Address Map Register 2
  [27:24] ADDRMAP_COL_B5 — - Full bus width mode: Selects the HIF address bit used as column address bit 5.- Half bus width mode: Selects the HIF address bit used as column address bit 6. - Quarter bus width mode: Selects the HIF address bit used as column address bit 7 . Valid Range: 0 to 7, and 15 Internal Base: 5 The selected HIF address bit is determined by adding the internal base to the value of this field. If unused, set to 15 and then this column address bit is set to 0. Programming Mode: Static
  [19:16] ADDRMAP_COL_B4 — - Full bus width mode: Selects the HIF address bit used as column address bit 4.- Half bus width mode: Selects the HIF address bit used as column address bit 5. - Quarter bus width mode: Selects the HIF address bit used as column address bit 6. Valid Range: 0 to 7, and 15 Internal Base: 4 The selected HIF address bit is determined by adding the internal base to the value of this field. If unused, set to 15 and then this column address bit is set to 0. Programming Mode: Static
  [11:8] ADDRMAP_COL_B3 — - Full bus width mode: Selects the HIF address bit used as column address bit 3.- Half bus width mode: Selects the HIF address bit used as column address bit 4. - Quarter bus width mode: Selects the HIF address bit used as column address bit 5. Valid Range: 0 to 7 Internal Base: 3 The selected HIF address bit is determined by adding the internal base to the value of this field. Note, if UMCTL2_INCL_ARB=1, MEMC_BURST_LENGTH=16, Full bus width (DDRCTL_MSTR.data_bus_width=00) and BL16 (DDRCTL_MSTR.burst_rdwr=1000), it is recommended to program this to 0. Programming Mode: Static
  [3:0] ADDRMAP_COL_B2 — - Full bus width mode: Selects the HIF address bit used as column address bit 2.- Half bus width mode: Selects the HIF address bit used as column address bit 3. - Quarter bus width mode: Selects the HIF address bit used as column address bit 4. Valid Range: 0 to 7 Internal Base: 2 The selected HIF address bit is determined by adding the internal base to the value of this field. Note, if UMCTL2_INCL_ARB=1 and MEMC_BURST_LENGTH=8, it is required to program this to 0 unless: - in Half or Quarter bus width (DDRCTL_MSTR.data_bus_width!=00) and - PCCFG.bl_exp_mode==1 and either - In DDR4 and DDRCTL_ADDRMAP8.addrmap_bg_b0==0 or - In LPDDR4 and DDRCTL_ADDRMAP1.addrmap_bank_b0==0 If UMCTL2_INCL_ARB=1 and MEMC_BURST_LENGTH=16, it is required to program this to 0 unless: - in Half or Quarter bus width (DDRCTL_MSTR.data_bus_width!=00) and - PCCFG.bl_exp_mode==1 and - In DDR4 and DDRCTL_ADDRMAP8.addrmap_bg_b0==0 Otherwise, if MEMC_BURST_LENGTH=8 and Full Bus Width (DDRCTL_MSTR.data_bus_width==00), it is recommended to program this to 0 so that HIF[2] maps to column address bit 2. If MEMC_BURST_LENGTH=16 and Full Bus Width (DDRCTL_MSTR.data_bus_width==00), it is recommended to program this to 0 so that HIF[2] maps to column address bit 2. If MEMC_BURST_LENGTH=16 and Half Bus Width (DDRCTL_MSTR.data_bus_width==01), it is recommended to program this to 0 so that HIF[2] maps to column address bit 3. Programming Mode: Static
